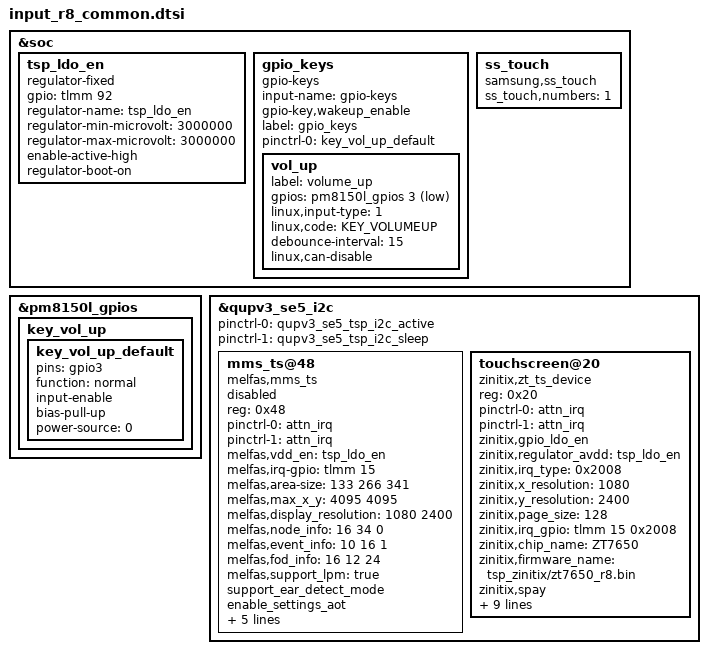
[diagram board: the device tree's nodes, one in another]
/* Copyright (c) 2016-2017, The Linux Foundation. All rights reserved.
 *
 * This program is free software; you can redistribute it and/or modify
 * it under the terms of the GNU General Public License version 2 and
 * only version 2 as published by the Free Software Foundation.
 *
 * This program is distributed in the hope that it will be useful,
 * but WITHOUT ANY WARRANTY; without even the implied warranty of
 * MERCHANTABILITY or FITNESS FOR A PARTICULAR PURPOSE.  See the
 * GNU General Public License for more details.
 */

#include <dt-bindings/input/input.h>

/delete-node/ &gpio_keys;
&soc {
	tsp_ldo_en {
		compatible = "regulator-fixed";
		gpio = <&tlmm 92 0>;
		regulator-name = "tsp_ldo_en";
		regulator-min-microvolt = <3000000>;
		regulator-max-microvolt = <3000000>;
		enable-active-high;
		regulator-boot-on;
	};

	gpio_keys: gpio_keys {
		status = "ok";
		compatible = "gpio-keys";
		input-name = "gpio-keys";
		gpio-key,wakeup_enable;
		label = "gpio_keys";

		pinctrl-names = "default";
		pinctrl-0 = <&key_vol_up_default>;

		vol_up {
			label = "volume_up";
			gpios = <&pm8150l_gpios 3 GPIO_ACTIVE_LOW>;
			linux,input-type = <1>;
			linux,code = <KEY_VOLUMEUP>;
			debounce-interval = <15>;
			linux,can-disable;
		};
	};

	ss_touch {
		compatible = "samsung,ss_touch";
		ss_touch,numbers = <1>;
	};
};

/delete-node/ &key_vol_up_default;

&pm8150l_gpios {
	key_vol_up {
		key_vol_up_default: key_vol_up_default {
			pins = "gpio3";
			function = "normal";
			input-enable;
			bias-pull-up;
			power-source = <0>;
		};
	};
};

&qupv3_se5_i2c {
	pinctrl-0 = <&qupv3_se5_tsp_i2c_active>;
	pinctrl-1 = <&qupv3_se5_tsp_i2c_sleep>;
	status = "ok";
	mms_ts@48 {
		compatible = "melfas,mms_ts";
		status = "disabled";
		reg = <0x48>;
		pinctrl-names = "on_state", "off_state";
		pinctrl-0 = <&attn_irq>;
		pinctrl-1 = <&attn_irq>;
		melfas,vdd_en = "tsp_ldo_en";
		/*melfas,io_en = "tsp_io";*/
		melfas,irq-gpio = <&tlmm 15 0x2008>;
		melfas,area-size = <133 266 341>; /* indicator: 24dp navigator:48dp edge:60px dpi=320 */
		melfas,max_x_y = <4095 4095>;	/* x & y */
		melfas,display_resolution = <1080 2400>;
		melfas,node_info = <16 34 0>;	/* x & y & key */
		melfas,event_info = <10 16 1>;		/* event format & event size */
		melfas,fod_info = <16 12 24>;	/* tx, rx, vi size */
		melfas,support_lpm = "true";
		support_ear_detect_mode;
		enable_settings_aot;
		support_open_short_test;
		support_fod;
		melfas,support_protos;
		/* This is for the firmware */
		melfas,fw_name = "tsp_melfas/mss100_r8.bin";
		melfas,gpio-en = <&tlmm 92 0>;
	};

	touchscreen@20 {
		compatible = "zinitix,zt_ts_device";
		status = "ok";
		reg = <0x20>;
		pinctrl-names = "on_state", "off_state";
		pinctrl-0 = <&attn_irq>;
		pinctrl-1 = <&attn_irq>;
		zinitix,gpio_ldo_en;
		zinitix,regulator_avdd = "tsp_ldo_en";
		zinitix,irq_type = <0x2008>;
		zinitix,x_resolution = <1080>;
		zinitix,y_resolution = <2400>;
		zinitix,page_size = <128>;
		zinitix,irq_gpio = <&tlmm 15 0x2008>;

		/* This part is for firmware */
		zinitix,chip_name = "ZT7650";
		zinitix,firmware_name = "tsp_zinitix/zt7650_r8.bin";

		/* feature */
		zinitix,spay;
		zinitix,aod;
		zinitix,aot;
		zinitix,mis_cal_check;
		support_ear_detect_mode;
		support_dex_mode;
		support_open_short_test;

		/* calibration */
		zinitix,tclm_level = <2>;
		zinitix,afe_base = <0x0018>;
		zinitix,ss_touch_num = <1>;
	};
};

